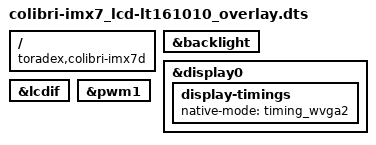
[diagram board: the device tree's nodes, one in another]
// Enable the parallel RGB interface with settings for 7" Displays on the Colibri iMX7

/dts-v1/;
/plugin/;

/ {
	compatible = "toradex,colibri-imx7d",
		     "toradex,colibri-imx7s";
};

&backlight {
	status = "okay";
};

&display0 {
	display-timings {
		native-mode = <&timing_wvga2>;
	};
};

&lcdif {
	status = "okay";
};

&pwm1 {
	status = "okay";
};
